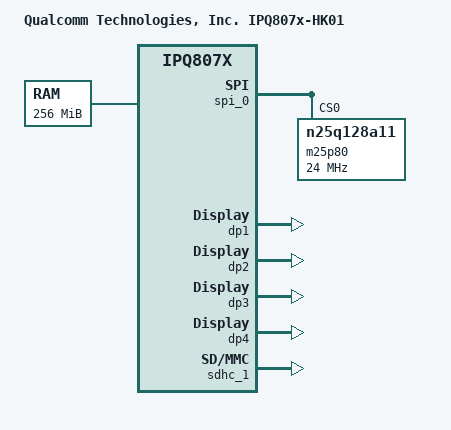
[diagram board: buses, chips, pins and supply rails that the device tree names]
/dts-v1/;
/*
 * Copyright (c) 2016, The Linux Foundation. All rights reserved.
 *
 * Permission to use, copy, modify, and/or distribute this software for any
 * purpose with or without fee is hereby granted, provided that the above
 * copyright notice and this permission notice appear in all copies.
 *
 * THE SOFTWARE IS PROVIDED "AS IS" AND THE AUTHOR DISCLAIMS ALL WARRANTIES
 * WITH REGARD TO THIS SOFTWARE INCLUDING ALL IMPLIED WARRANTIES OF
 * MERCHANTABILITY AND FITNESS. IN NO EVENT SHALL THE AUTHOR BE LIABLE FOR
 * ANY SPECIAL, DIRECT, INDIRECT, OR CONSEQUENTIAL DAMAGES OR ANY DAMAGES
 * WHATSOEVER RESULTING FROM LOSS OF USE, DATA OR PROFITS, WHETHER IN AN
 * ACTION OF CONTRACT, NEGLIGENCE OR OTHER TORTIOUS ACTION, ARISING OUT OF
 * OR IN CONNECTION WITH THE USE OR PERFORMANCE OF THIS SOFTWARE.
 */
#include "qcom-ipq807x-soc.dtsi"

/ {
	#address-cells = <0x2>;
	#size-cells = <0x2>;
	model = "Qualcomm Technologies, Inc. IPQ807x-HK01";
	compatible = "qcom,ipq807x-hk01", "qcom,ipq807x";
	qcom,msm-id = <0x125 0x0>;
	interrupt-parent = <&intc>;
	qcom,board-id = <0x10 0x0>;

	aliases {
		sdhc1 = &sdhc_1; /* SDC1 eMMC slot */
	};

	cpus {
		#address-cells = <0x1>;
		#size-cells = <0x0>;

		cpu-map {

			cluster0 {

				core0 {
					cpu = <&CPU0>;
				};

				core1 {
					cpu = <&CPU1>;
				};

				core2 {
					cpu = <&CPU2>;
				};

				core3 {
					cpu = <&CPU3>;
				};
			};

		};

		CPU0: cpu@0 {
			device_type = "cpu";
			compatible = "arm,cortex-a53";
			reg = <0x0>;
			clocks = <&gcc GCC_DUMMY_CLK>;
			clock-names = "cpu";
			operating-points-v2 = <&cpu0_opp_table>;
			enable-method = "qcom,arm-cortex-acc";
			qcom,acc = <&acc0>;
			next-level-cache = <&L2_0>;

			L2_0: l2-cache {
				compatible = "arm,arch-cache";
				cache-level = <0x2>;
			};
		};

		CPU1: cpu@1 {
			device_type = "cpu";
			compatible = "arm,cortex-a53";
			enable-method = "qcom,arm-cortex-acc";
			reg = <0x1>;
			clocks = <&gcc GCC_DUMMY_CLK>;
			clock-names = "cpu";
			operating-points-v2 = <&cpu0_opp_table>;
			qcom,acc = <&acc1>;
			next-level-cache = <&L2_0>;
		};

		CPU2: cpu@2 {
			device_type = "cpu";
			compatible = "arm,cortex-a53";
			enable-method = "qcom,arm-cortex-acc";
			reg = <0x2>;
			clocks = <&gcc GCC_DUMMY_CLK>;
			clock-names = "cpu";
			operating-points-v2 = <&cpu0_opp_table>;
			qcom,acc = <&acc2>;
			next-level-cache = <&L2_0>;
		};

		CPU3: cpu@3 {
			device_type = "cpu";
			compatible = "arm,cortex-a53";
			enable-method = "qcom,arm-cortex-acc";
			reg = <0x3>;
			clocks = <&gcc GCC_DUMMY_CLK>;
			clock-names = "cpu";
			operating-points-v2 = <&cpu0_opp_table>;
			qcom,acc = <&acc3>;
			next-level-cache = <&L2_0>;
		};

	};

	cpu0_opp_table: opp_table0 {
		compatible = "operating-points-v2";
		opp-shared;

		opp00 {
			opp-hz = /bits/ 64 <1036800000>;
			opp-microvolt = <670000>;
			clock-latency-ns = <200000>;
		};
		opp01 {
			opp-hz = /bits/ 64 <1689600000>;
			opp-microvolt = <735000>;
			clock-latency-ns = <200000>;
		};
		opp02 {
			opp-hz = /bits/ 64 <1843200000>;
			opp-microvolt = <800000>;
			clock-latency-ns = <200000>;
		};
		opp03 {
			opp-hz = /bits/ 64 <1958400000>;
			opp-microvolt = <850000>;
			clock-latency-ns = <200000>;
		};
		opp04 {
			opp-hz = /bits/ 64 <2016000000>;
			opp-microvolt = <905000>;
			clock-latency-ns = <200000>;
		};
		opp05 {
			opp-hz = /bits/ 64 <2208000000>;
			opp-microvolt = <990000>;
			clock-latency-ns = <200000>;
		};
	};

	chosen {
		linux,initrd-end = <0x43400000>;
		linux,initrd-start = <0x42000000>;
		bootargs = "console=ttyMSM0,115200,n8 root=/dev/ram0 rw \
			    init=/init";
	};

	memory {
		device_type = "memory";
		reg = <0x0 0x40000000 0x0 0x10000000>;
	};

	/*
	 * +=========+==============+========================+
	 * |        |              |                         |
	 * | Region | Start Offset |          Size           |
	 * |        |              |                         |
	 * +--------+--------------+-------------------------+
	 * |        |              |                         |
	 * |        |              |                         |
	 * |  NSS   |  0x40000000  |          16MB           |
	 * |        |              |                         |
	 * |        |              |                         |
	 * +--------+--------------+-------------------------+
	 * |        |              |                         |
	 * |        |              |                         |
	 * |        |              |                         |
	 * |        |              |                         |
	 * | Linux  |  0x41000000  | Depends on total memory |
	 * |        |              |                         |
	 * |        |              |                         |
	 * |        |              |                         |
	 * |        |              |                         |
	 * +--------+--------------+-------------------------+
	 * | uboot  |  0x4A600000  |           4MB           |
	 * +--------+--------------+-------------------------+
	 * |  SBL   |  0x4AA00000  |           1MB           |
	 * +--------+--------------+-------------------------+
	 * |  smem  |  0x4AB00000  |           1MB           |
	 * +--------+--------------+-------------------------+
	 * |        |              |                         |
	 * |TZ+APPS |  0x4AC00000  |           4MB           |
	 * |        |              |                         |
	 * +--------+--------------+-------------------------+
	 * |        |              |                         |
	 * |        |              |                         |
	 * |        |              |                         |
	 * |   Q6   |  0x4B000000  |          80MB           |
	 * |        |              |                         |
	 * |        |              |                         |
	 * |        |              |                         |
	 * +--------+--------------+-------------------------+
	 * |                                                 |
	 * |      Linux Memory for variants above 256MB      |
	 * |                                                 |
	 * +=================================================+
	 */

	reserved-memory {
		#address-cells = <2>;
		#size-cells = <2>;
		ranges;

		nss@40000000 {
			no-map;
			reg = <0x0 0x40000000 0x0 0x01000000>;
		};

		uboot@4a600000 {
			no-map;
			reg = <0x0 0x4a600000 0x0 0x00400000>;
		};

		sbl@4aa00000 {
			no-map;
			reg = <0x0 0x4aa00000 0x0 0x00100000>;
		};

		smem@4ab00000 {
			no-map;
			reg = <0x0 0x4ab00000 0x0 0x00100000>;
		};

		tz@4ac00000 {	/* TZ and TZ_APPS */
			no-map;
			reg = <0x0 0x4ac00000 0x0 0x00400000>;
		};

		wcnss@4ab00000 {
			no-map;
			reg = <0x0 0x4b000000 0x0 0x04ffffff>;
		};
	};
};

&soc {

	acc0:clock-controller@b188000 {
		compatible = "qcom,arm-cortex-acc";
		reg = <0x0b188000 0x1000>;
	};

	acc1:clock-controller@b198000 {
		compatible = "qcom,arm-cortex-acc";
		reg = <0x0b198000 0x1000>;
	};

	acc2:clock-controller@b1a8000 {
		compatible = "qcom,arm-cortex-acc";
		reg = <0x0b1a8000 0x1000>;
	};

	acc3:clock-controller@b1b8000 {
		compatible = "qcom,arm-cortex-acc";
		reg = <0x0b1b8000 0x1000>;
	};

	spi_0: spi@78b5000 { /* BLSP1 QUP1 */
		#pinctrl-0 = <&spi_0_pins>;
		#pinctrl-names = "default";
		status = "ok";

		m25p80@0 {
			#address-cells = <1>;
			#size-cells = <1>;
			reg = <0>;
			compatible = "n25q128a11";
			linux,modalias = "m25p80", "n25q128a11";
			spi-max-frequency = <24000000>;
			use-default-sizes;
		};
	};

	dp1 {
		device_type = "network";
		compatible = "qcom,nss-dp";
		qcom,id = <1>;
		local-mac-address = [000000000000];
	};

	dp2 {
		device_type = "network";
		compatible = "qcom,nss-dp";
		qcom,id = <2>;
		local-mac-address = [000000000000];
	};

	dp3 {
		device_type = "network";
		compatible = "qcom,nss-dp";
		qcom,id = <3>;
		local-mac-address = [000000000000];
	};

	dp4 {
		device_type = "network";
		compatible = "qcom,nss-dp";
		qcom,id = <4>;
		local-mac-address = [000000000000];
	};

	nss-common {
		compatible = "qcom,nss-common";
		reg = <0x01d00000 0x1000>;
		reg-names = "nss_fpb_base";
		clocks = <&gcc GCC_DUMMY_CLK>, <&gcc GCC_DUMMY_CLK>;
		clock-names = "nss-core-clk", "nss-tcm-clk";
	};

	nss0: nss@40000000 {
		compatible = "qcom,nss";
		interrupts = <0 377 0x1>, <0 378 0x1>, <0 379 0x1>, <0 380 0x1>,
			     <0 381 0x1>;
		reg = <0x39000000 0x1000>, <0x38000000 0x30000>,
		      <0x0b111000 0x1000>;
		reg-names = "nphys", "vphys", "qgic-phys";
		clocks = <&gcc GCC_DUMMY_CLK>, <&gcc GCC_DUMMY_CLK>,
			 <&gcc GCC_DUMMY_CLK>;
		clock-names = "nss-core-clk", "nss-tcm-src",
			      "nss-tcm-clk";
		resets = <&gcc GCC_DUMMY_CLK>,
			 <&gcc GCC_DUMMY_CLK>,
			 <&gcc GCC_DUMMY_CLK>,
			 <&gcc GCC_DUMMY_CLK>;
		reset-names = "clkrst-clamp", "clamp", "ahb", "axi";
		qcom,id = <0>;
		qcom,num-queue = <2>;
		qcom,num-irq = <5>;
		qcom,load-addr = <0x40000000>;
		qcom,ipv4-enabled;
		qcom,ipv6-enabled;
		qcom,wlanredirect-enabled;
		qcom,tun6rd-enabled;
		qcom,l2tpv2-enabled;
		qcom,portid-enabled;
		qcom,pppoe-enabled;
		qcom,pptp-enabled;
		qcom,tunipip6-enabled;
		qcom,shaping-enabled;
		qcom,wlan-dataplane-offload-enabled;
	};
};

&sdhc_1{
	qcom,clk-rates = <400000 25000000 50000000 100000000 \
			 192000000 384000000>;
	qcom,bus-speed-mode = "HS200_1p8v", "DDR_1p8v";
	qcom,nonremovable;
	status = "ok";
};
